# ioADuCM4050 register map
Registers are 16-bit, access not given, no defined reset value unless marked. A register's access mark holds for its fields unless they carry their own. Addresses are absolute; registers are grouped by the start of their names; [hi:lo] are bit positions; {n}, {i} and the like mark numbered series.

## RTC1
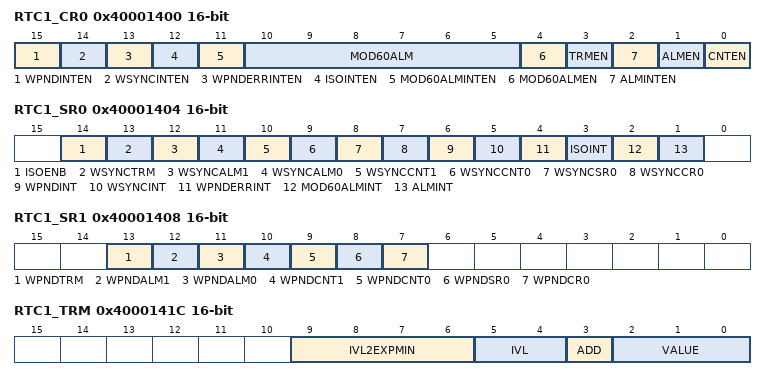
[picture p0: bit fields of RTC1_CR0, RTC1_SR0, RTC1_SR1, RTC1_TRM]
0x40001400 RTC1_CR0
  [15] WPNDINTEN, [14] WSYNCINTEN, [13] WPNDERRINTEN, [12] ISOINTEN, [11] MOD60ALMINTEN, [10:5] MOD60ALM, [4] MOD60ALMEN, [3] TRMEN, [2] ALMINTEN, [1] ALMEN, [0] CNTEN
0x40001404 RTC1_SR0
  [14] ISOENB, [13] WSYNCTRM, [12] WSYNCALM1, [11] WSYNCALM0, [10] WSYNCCNT1, [9] WSYNCCNT0, [8] WSYNCSR0, [7] WSYNCCR0, [6] WPNDINT, [5] WSYNCINT, [4] WPNDERRINT, [3] ISOINT, [2] MOD60ALMINT, [1] ALMINT
0x40001408 RTC1_SR1
  [13] WPNDTRM, [12] WPNDALM1, [11] WPNDALM0, [10] WPNDCNT1, [9] WPNDCNT0, [8] WPNDSR0, [7] WPNDCR0
0x4000140C RTC1_CNT0
0x40001410 RTC1_CNT1
0x40001414 RTC1_ALM0
0x40001418 RTC1_ALM1
0x4000141C RTC1_TRM
  [9:6] IVL2EXPMIN, [5:4] IVL, [3] ADD, [2:0] VALUE
0x40001420 RTC1_GWY
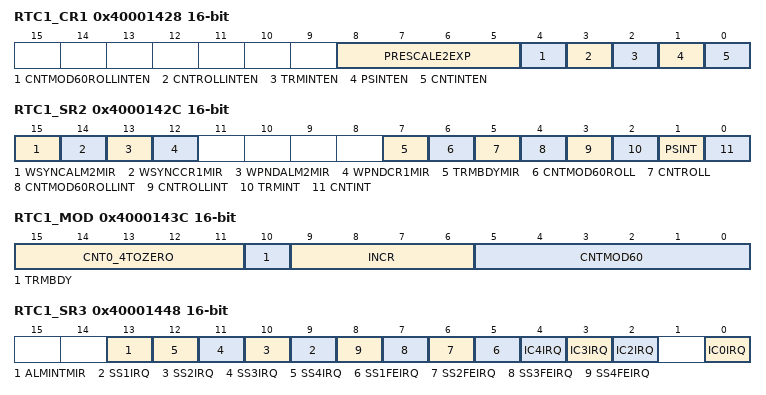
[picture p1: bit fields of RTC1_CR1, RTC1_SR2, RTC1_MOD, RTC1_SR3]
0x40001428 RTC1_CR1
  [8:5] PRESCALE2EXP, [4] CNTMOD60ROLLINTEN, [3] CNTROLLINTEN, [2] TRMINTEN, [1] PSINTEN, [0] CNTINTEN
0x4000142C RTC1_SR2
  [15] WSYNCALM2MIR, [14] WSYNCCR1MIR, [13] WPNDALM2MIR, [12] WPNDCR1MIR, [7] TRMBDYMIR, [6] CNTMOD60ROLL, [5] CNTROLL, [4] CNTMOD60ROLLINT, [3] CNTROLLINT, [2] TRMINT, [1] PSINT, [0] CNTINT
0x40001430 RTC1_SNAP0
0x40001434 RTC1_SNAP1
0x40001438 RTC1_SNAP2
  [14:0] VALUE
0x4000143C RTC1_MOD
  [15:11] CNT0_4TOZERO, [10] TRMBDY, [9:6] INCR, [5:0] CNTMOD60
0x40001440 RTC1_CNT2
  [14:0] VALUE
0x40001444 RTC1_ALM2
  [14:0] VALUE
0x40001448 RTC1_SR3
  [13] ALMINTMIR, [n+8] SS{n}IRQ (n=1..4), [n+4] SS{n}FEIRQ (n=1..4), [4] IC4IRQ, [3] IC3IRQ, [2] IC2IRQ, [0] IC0IRQ
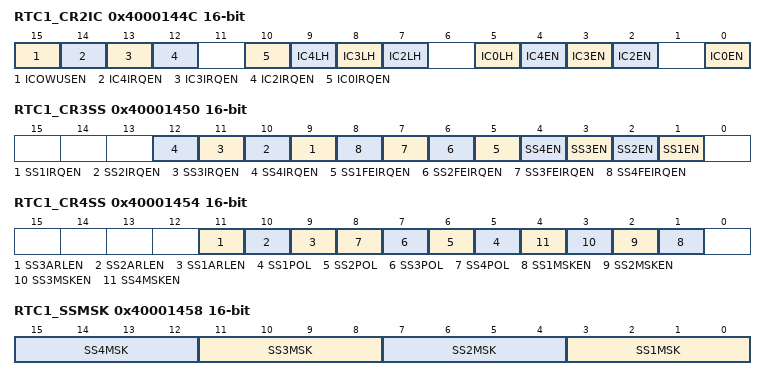
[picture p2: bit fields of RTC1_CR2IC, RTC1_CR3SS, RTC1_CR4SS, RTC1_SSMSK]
0x4000144C RTC1_CR2IC
  [15] ICOWUSEN, [14] IC4IRQEN, [13] IC3IRQEN, [12] IC2IRQEN, [10] IC0IRQEN, [9] IC4LH, [8] IC3LH, [7] IC2LH, [5] IC0LH, [4] IC4EN, [3] IC3EN, [2] IC2EN, [0] IC0EN
0x40001450 RTC1_CR3SS
  [n+8] SS{n}IRQEN (n=1..4), [n+4] SS{n}FEIRQEN (n=1..4), [n] SS{n}EN (n=1..4)
0x40001454 RTC1_CR4SS
  [11] SS3ARLEN, [10] SS2ARLEN, [9] SS1ARLEN, [n+4] SS{n}POL (n=1..4), [n] SS{n}MSKEN (n=1..4)
0x40001458 RTC1_SSMSK
  [4n-1:4n-4] SS{n}MSK (n=1..4)
{0x4000145C+4i} RTC1_IC{i} (i=2..4)
{0x4000146C+4i} RTC1_SS{i} (i=1..4)
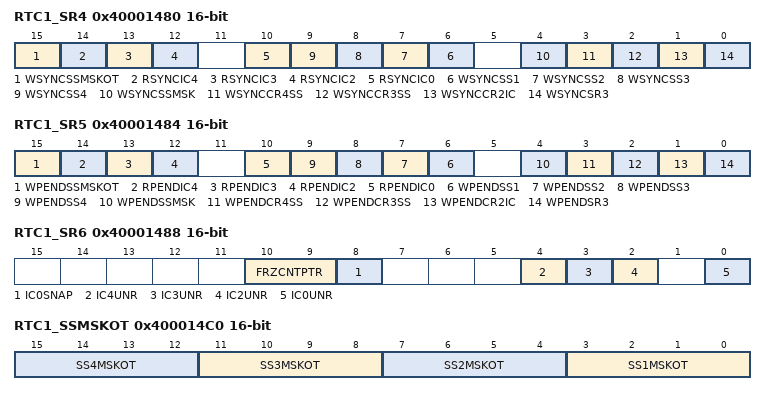
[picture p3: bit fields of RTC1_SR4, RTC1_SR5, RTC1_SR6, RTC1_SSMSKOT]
0x40001480 RTC1_SR4
  [15] WSYNCSSMSKOT, [14] RSYNCIC4, [13] RSYNCIC3, [12] RSYNCIC2, [10] RSYNCIC0, [n+5] WSYNCSS{n} (n=1..4), [4] WSYNCSSMSK, [3] WSYNCCR4SS, [2] WSYNCCR3SS, [1] WSYNCCR2IC, [0] WSYNCSR3
0x40001484 RTC1_SR5
  [15] WPENDSSMSKOT, [14] RPENDIC4, [13] RPENDIC3, [12] RPENDIC2, [10] RPENDIC0, [n+5] WPENDSS{n} (n=1..4), [4] WPENDSSMSK, [3] WPENDCR4SS, [2] WPENDCR3SS, [1] WPENDCR2IC, [0] WPENDSR3
0x40001488 RTC1_SR6
  [10:9] FRZCNTPTR, [8] IC0SNAP, [4] IC4UNR, [3] IC3UNR, [2] IC2UNR, [0] IC0UNR
0x4000148C RTC1_SS1TGT
0x40001490 RTC1_FRZCNT
0x40001494 RTC1_SS2TGT
0x40001498 RTC1_SS3TGT
{0x4000149C+4i} RTC1_SS{i}LOWDUR (i=1..3)
{0x400014AC+4i} RTC1_SS{i}HIGHDUR (i=1..3)
0x400014C0 RTC1_SSMSKOT
  [4n-1:4n-4] SS{n}MSKOT (n=1..4)
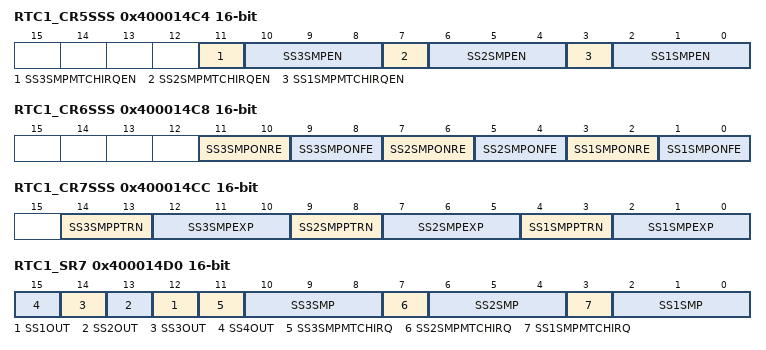
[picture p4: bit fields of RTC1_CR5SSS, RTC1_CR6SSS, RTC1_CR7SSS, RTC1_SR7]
0x400014C4 RTC1_CR5SSS
  [11] SS3SMPMTCHIRQEN, [10:8] SS3SMPEN, [7] SS2SMPMTCHIRQEN, [6:4] SS2SMPEN, [3] SS1SMPMTCHIRQEN, [2:0] SS1SMPEN
0x400014C8 RTC1_CR6SSS
  [11:10] SS3SMPONRE, [9:8] SS3SMPONFE, [7:6] SS2SMPONRE, [5:4] SS2SMPONFE, [3:2] SS1SMPONRE, [1:0] SS1SMPONFE
0x400014CC RTC1_CR7SSS
  [14:13] SS3SMPPTRN, [12:10] SS3SMPEXP, [9:8] SS2SMPPTRN, [7:5] SS2SMPEXP, [4:3] SS1SMPPTRN, [2:0] SS1SMPEXP
0x400014D0 RTC1_SR7
  [n+11] SS{n}OUT (n=1..4), [11] SS3SMPMTCHIRQ, [10:8] SS3SMP, [7] SS2SMPMTCHIRQ, [6:4] SS2SMP, [3] SS1SMPMTCHIRQ, [2:0] SS1SMP
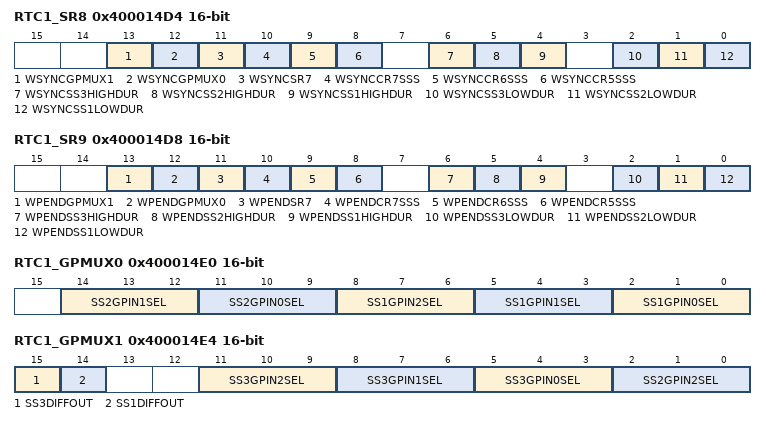
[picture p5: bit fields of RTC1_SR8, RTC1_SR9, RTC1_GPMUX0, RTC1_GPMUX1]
0x400014D4 RTC1_SR8
  [13] WSYNCGPMUX1, [12] WSYNCGPMUX0, [11] WSYNCSR7, [10] WSYNCCR7SSS, [9] WSYNCCR6SSS, [8] WSYNCCR5SSS, [6] WSYNCSS3HIGHDUR, [5] WSYNCSS2HIGHDUR, [4] WSYNCSS1HIGHDUR, [2] WSYNCSS3LOWDUR, [1] WSYNCSS2LOWDUR, [0] WSYNCSS1LOWDUR
0x400014D8 RTC1_SR9
  [13] WPENDGPMUX1, [12] WPENDGPMUX0, [11] WPENDSR7, [10] WPENDCR7SSS, [9] WPENDCR6SSS, [8] WPENDCR5SSS, [6] WPENDSS3HIGHDUR, [5] WPENDSS2HIGHDUR, [4] WPENDSS1HIGHDUR, [2] WPENDSS3LOWDUR, [1] WPENDSS2LOWDUR, [0] WPENDSS1LOWDUR
0x400014E0 RTC1_GPMUX0
  [14:12] SS2GPIN1SEL, [11:9] SS2GPIN0SEL, [8:6] SS1GPIN2SEL, [5:3] SS1GPIN1SEL, [2:0] SS1GPIN0SEL
0x400014E4 RTC1_GPMUX1
  [15] SS3DIFFOUT, [14] SS1DIFFOUT, [11:9] SS3GPIN2SEL, [8:6] SS3GPIN1SEL, [5:3] SS3GPIN0SEL, [2:0] SS2GPIN2SEL
